AUTOSAR XML (schema 00050)
package /FCADT/ComponentTypes
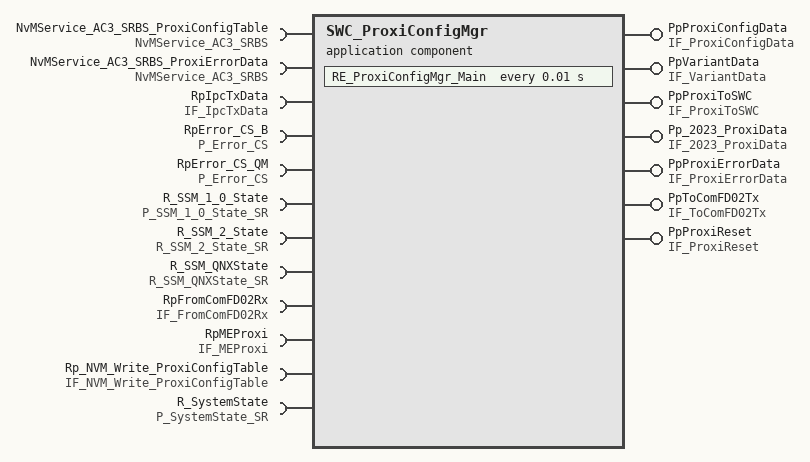
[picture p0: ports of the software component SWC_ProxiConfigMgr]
  application sw component type SWC_ProxiConfigMgr
    provide port PpProxiConfigData: nonqueued-sender-com-spec{data-element=ProxiData, init-value=fields=[bValid:0, ConfigCode:11 x 0, TesterCode:10 x 0, ProductionDate:[0, 0, 0, 0], CanNode14trscm_uint8:0, Variant_ID:0, CanNode27Asm_uint8:0, CanNode63ttm_uint8:0, CanNode67dtcm_uint8:0, CanNode95itcm_uint8:0, StopandStart:0, DriverSide:0, Tyresize_uint16:0, Wheelbase:0, Rearviewcamera:0, Parkwithstop:0, SteeringRatio_uint8:0, Gearboxtype:0, Drivetypevariant:0, Pamtuningset:0, Semiautopark:0, VehicleLineConfiguration_uint8:0, CountryCode_uint8:0, Srt:0, PAMConfig_uint8:0, ModelYear_uint8:0, Hybridtype:0, Pulloutcontrol:0, Surroundviewcamera:0, Forwardfacingcamera:0, Autonomylevel:0, Fullautomaticparking:0, Radiodisplay:0, Mirrortype:0, Auxiliarycamera:0, Trailerreverseguide:0, Trailersurround:0, Trailerreversesteering:0, Trailerhitchassist:0, CVPAM_Presence_uint8:0, SideDistanceWarning:0, PROXIWriteCounter:0]}, provided-interface=IF_ProxiConfigData
    provide port PpVariantData: nonqueued-sender-com-spec{data-element=Variant, init-value=constant-reference=init_Variant}, provided-interface=IF_VariantData
    5 x require port:
      NvMService_AC3_SRBS_ProxiConfigTable: required-com-specs=[WriteBlock, SetRamBlockStatus, ReadBlock, InvalidateNvBlock, GetErrorStatus, EraseBlock], required-interface=NvMService_AC3_SRBS
      NvMService_AC3_SRBS_ProxiErrorData: required-com-specs=[WriteBlock, SetRamBlockStatus, ReadBlock, InvalidateNvBlock, GetErrorStatus, EraseBlock], required-interface=NvMService_AC3_SRBS
      RpIpcTxData: client-com-spec=IPC_Write_v, required-interface=IF_IpcTxData
      RpError_CS_B: client-com-spec=ReportErrorStatus1_0_B, required-interface=P_Error_CS
      RpError_CS_QM: client-com-spec=ReportErrorStatus1_0_QM, required-interface=P_Error_CS
    provide port PpProxiToSWC: provided-interface=IF_ProxiToSWC
      provided-com-specs:
        data-element=TyreSz_u16, init-value=0
        data-element=SurroundViewCam_u8, init-value=0
        data-element=Fullautomaticparking, init-value=0
        data-element=Pamtuningset, init-value=0
        data-element=Parkwithstop_u8, init-value=0
        data-element=Trailerhitchassist_u8, init-value=0
        data-element=PAMConfig_u8, init-value=0
        data-element=PRX_CanNod27_b, init-value=0
    require port R_SSM_1_0_State: nonqueued-receiver-com-spec{data-element=State_1_0, init-value=fields=[CoreStatus:0, LocalAppStatus:20 x 0]}, required-interface=P_SSM_1_0_State_SR
    require port R_SSM_2_State: required-interface=R_SSM_2_State_SR
      required-com-specs:
        data-element=State_2_0, init-value=fields=[CoreStatus:0, LocalAppStatus:20 x 0]
        data-element=State_2_1, filter=data-filter-type=ALWAYS, init-value=fields=[CoreStatus:0, LocalAppStatus:20 x 0]
    require port R_SSM_QNXState: nonqueued-receiver-com-spec{data-element=State_QNX, init-value=fields=[CoreStatus:0, LocalAppStatus:20 x 0]}, required-interface=R_SSM_QNXState_SR
    provide port Pp_2023_ProxiData: server-com-spec{operation=WriteData, queue-length=1}, provided-interface=IF_2023_ProxiData
    provide port PpProxiErrorData: nonqueued-sender-com-spec{data-element=Error, init-value=fields=[ErrorFound:[0, 0, 0], ByteWithError:[0, 0, 0], BitInformationMask:[0, 0, 0]]}, provided-interface=IF_ProxiErrorData
    provide port PpToComFD02Tx: provided-interface=IF_ToComFD02Tx
      provided-com-specs:
        data-element=CurrentCanNMState_FD02_PAM, init-value=0
        data-element=CurrentFailSts_FD02_PAM, init-value=0
        data-element=DES_FD02_PAM, init-value=0
        data-element=Digit_{01..11}_PAM, init-value=0
        data-element=EOL_FD02_PAM, init-value=0
        data-element=GenericFailSts_FD02_PAM, init-value=0
        {data-element=N_PDU, init-value=[rule-based-values={rule=FILL_UNTIL_END, rule-arguments=0}]}
        data-element=PreviousCanNMState_FD02_PAM, init-value=0
        {data-element=StayActiveSource_FD02_PAM, init-value=[rule-based-values={rule=FILL_UNTIL_END, rule-arguments=0}]}
        data-element=THA_EPB_Req, init-value=0
        data-element=THA_Speed_Limit, init-value=0
        data-element=THA_SpeedLimit_Req, init-value=0
        data-element=THA_STAT, init-value=0
        data-element=THA_SteeringDamping, init-value=78.125
        data-element=THA_SteeringTorqueInfo, init-value=0
        data-element=THA_SteeringTorqueReq, init-value=0
        data-element=Trailer_Angle, init-value=0
        data-element=Trailer_Angle_Sign, init-value=0
        data-element=Trailer_Calibration, init-value=0
        data-element=TrlrHitchLight_Cntrl, init-value=0
        data-element=TRSC_PopupDisp_Info, init-value=0
        data-element=TRSC_SpeedLimit_Req, init-value=0
        data-element=TRSC_STAT, init-value=1
        data-element=TRSC_SteeringDamping, init-value=100
        data-element=TRSC_SteeringTorqueInfo, init-value=0
        data-element=TRSC_SteeringTorqueReq, init-value=0
        data-element=TRSC_VehicleStop_Req, init-value=3
        data-element=TRSCMoreCamRQSts, init-value=0
        data-element=WakeupSource_FD02_PAM, init-value=0
        data-element=TRSC_PopupDisp_Info2, init-value=0
    require port RpFromComFD02Rx: required-interface=IF_FromComFD02Rx
      required-com-specs:
        data-element=Altitude_RMSE_C2, init-value=255
        data-element=Battery_Volt_1, init-value=0
        data-element=BSM_THA_Brk_Resp, init-value=0
        data-element=CurrentCanNMState_FD01_BCM, init-value=0
        data-element=CurrentCanNMState_FD01_SGW, init-value=0
        data-element=CurrentCanNMState_FD02_BCM, init-value=0
        data-element=CurrentCanNMState_FD02_BSM2, init-value=0
        data-element=CurrentCanNMState_FD02_CADM2, init-value=0
        data-element=CurrentCanNMState_FD02_EPS, init-value=0
        data-element=CurrentCanNMState_FD02_ORC, init-value=0
        data-element=CurrentCanNMState_FD02_SGW, init-value=0
        data-element=CurrentCanNMState_FD02_TRLR_REV, init-value=0
        data-element=CurrentCanNMState_FD03_BCM, init-value=0
        data-element=CurrentCanNMState_FD03_SGW, init-value=0
        data-element=CurrentCanNMState_FD04_BCM, init-value=0
        data-element=CurrentCanNMState_FD08_SGW, init-value=0
        data-element=CurrentCanNMState_FD11_SGW, init-value=0
        data-element=CurrentFailSts_FD01_BCM, init-value=0
        data-element=CurrentFailSts_FD01_SGW, init-value=0
        data-element=CurrentFailSts_FD02_BCM, init-value=0
        data-element=CurrentFailSts_FD02_BSM2, init-value=0
        data-element=CurrentFailSts_FD02_CADM2, init-value=0
        data-element=CurrentFailSts_FD02_EPS, init-value=0
        data-element=CurrentFailSts_FD02_ORC, init-value=0
        data-element=CurrentFailSts_FD02_SGW, init-value=0
        data-element=CurrentFailSts_FD02_TRLR_REV, init-value=0
        data-element=CurrentFailSts_FD03_BCM, init-value=0
        data-element=CurrentFailSts_FD03_SGW, init-value=0
        data-element=CurrentFailSts_FD04_BCM, init-value=0
        data-element=CurrentFailSts_FD08_SGW, init-value=0
        data-element=CurrentFailSts_FD11_SGW, init-value=0
        data-element=DeltaTimestamp_IMUdata, init-value=255
        data-element=DES_FD01_BCM, init-value=0
        data-element=DES_FD01_SGW, init-value=0
        data-element=DES_FD02_BCM, init-value=0
        data-element=DES_FD02_BSM2, init-value=0
        data-element=DES_FD02_CADM2, init-value=0
        data-element=DES_FD02_EPS, init-value=0
        data-element=DES_FD02_ORC, init-value=0
        data-element=DES_FD02_SGW, init-value=0
        data-element=DES_FD02_TRLR_REV, init-value=0
        data-element=DES_FD03_BCM, init-value=0
        data-element=DES_FD03_SGW, init-value=0
        data-element=DES_FD04_BCM, init-value=0
        data-element=DES_FD08_SGW, init-value=0
        data-element=DES_FD11_SGW, init-value=0
        data-element=Digit_{01..11}, init-value=0
        data-element=EOL_FD01_BCM, init-value=0
        data-element=EOL_FD01_SGW, init-value=0
        data-element=EOL_FD02_BCM, init-value=0
        data-element=EOL_FD02_BSM2, init-value=0
        data-element=EOL_FD02_CADM2, init-value=0
        data-element=EOL_FD02_EPS, init-value=0
        data-element=EOL_FD02_ORC, init-value=0
        data-element=EOL_FD02_SGW, init-value=0
        data-element=EOL_FD02_TRLR_REV, init-value=0
        data-element=EOL_FD03_BCM, init-value=0
        data-element=EOL_FD03_SGW, init-value=0
        data-element=EOL_FD04_BCM, init-value=0
        data-element=EOL_FD08_SGW, init-value=0
        data-element=EOL_FD11_SGW, init-value=0
        data-element=EPBSts, init-value=0
        data-element=GenericFailSts_FD01_BCM, init-value=0
        data-element=GenericFailSts_FD01_SGW, init-value=0
        data-element=GenericFailSts_FD02_BCM, init-value=0
        data-element=GenericFailSts_FD02_BSM2, init-value=0
        data-element=GenericFailSts_FD02_CADM2, init-value=0
        data-element=GenericFailSts_FD02_EPS, init-value=0
        data-element=GenericFailSts_FD02_ORC, init-value=0
        data-element=GenericFailSts_FD02_SGW, init-value=0
        data-element=GenericFailSts_FD02_TRLR_REV, init-value=0
        data-element=GenericFailSts_FD03_BCM, init-value=0
        data-element=GenericFailSts_FD03_SGW, init-value=0
        data-element=GenericFailSts_FD04_BCM, init-value=0
        data-element=GenericFailSts_FD08_SGW, init-value=0
        data-element=GenericFailSts_FD11_SGW, init-value=0
        data-element=Heading_Angle_C2, init-value=65535
        data-element=IgnitionOnCounter, init-value=0
        data-element=LatAcceleration_C2, init-value=4095
        data-element=LatAccelerationOffset_BSM, init-value=255
        data-element=Latitude_RMSE_C2, init-value=255
        data-element=LHF_FastPulseCounter, init-value=0
        data-element=LHF_Spin, init-value=0
        data-element=LHFWheelSpeed, init-value=0
        data-element=LHR_FastPulseCounter, init-value=0
        data-element=LHR_Spin, init-value=0
        data-element=LHRWheelSpeed, init-value=0
        data-element=LongAcceleration_C2, init-value=4095
        data-element=LongAccelerationOffset_BSM, init-value=255
        data-element=Longitude_RMSE_C2, init-value=255
        data-element=OperationalModeSts, init-value=0
        data-element=Pitch_RMSE_C2, init-value=255
        data-element=PitchRate_C2, init-value=4095
        data-element=PreviousCanNMState_FD01_BCM, init-value=0
        data-element=PreviousCanNMState_FD01_SGW, init-value=0
        data-element=PreviousCanNMState_FD02_BCM, init-value=0
        data-element=PreviousCanNMState_FD02_BSM2, init-value=0
        data-element=PreviousCanNMState_FD02_CADM2, init-value=0
        data-element=PreviousCanNMState_FD02_EPS, init-value=0
        data-element=PreviousCanNMState_FD02_ORC, init-value=0
        data-element=PreviousCanNMState_FD02_SGW, init-value=0
        data-element=PreviousCanNMState_FD02_TRLR_REV, init-value=0
        data-element=PreviousCanNMState_FD03_BCM, init-value=0
        data-element=PreviousCanNMState_FD03_SGW, init-value=0
        data-element=PreviousCanNMState_FD04_BCM, init-value=0
        data-element=PreviousCanNMState_FD08_SGW, init-value=0
        data-element=PreviousCanNMState_FD11_SGW, init-value=0
        data-element=REF_VEH_SPEED, init-value=1023
        data-element=RemStActvSts, init-value=0
        data-element=RHF_FastPulseCounter, init-value=0
        data-element=RHF_Spin, init-value=0
        data-element=RHFWheelSpeed, init-value=0
        data-element=RHR_FastPulseCounter, init-value=0
        data-element=RHR_Spin, init-value=0
        data-element=RHRWheelSpeed, init-value=0
        data-element=Roll_RMSE_C2, init-value=255
        data-element=RollRate_C2, init-value=4095
        data-element=SBR1RowDriverSeatSts, init-value=3
        data-element=StayActiveSource_FD01_BCM, init-value=0
        data-element=StayActiveSource_FD01_SGW, init-value=0
        data-element=StayActiveSource_FD02_BCM, init-value=0
        data-element=StayActiveSource_FD02_BSM2, init-value=0
        data-element=StayActiveSource_FD02_CADM2, init-value=0
        data-element=StayActiveSource_FD02_EPS, init-value=0
        data-element=StayActiveSource_FD02_ORC, init-value=0
        data-element=StayActiveSource_FD02_SGW, init-value=0
        data-element=StayActiveSource_FD02_TRLR_REV, init-value=0
        data-element=StayActiveSource_FD03_BCM, init-value=0
        data-element=StayActiveSource_FD03_SGW, init-value=0
        data-element=StayActiveSource_FD04_BCM, init-value=0
        data-element=StayActiveSource_FD08_SGW, init-value=0
        data-element=StayActiveSource_FD11_SGW, init-value=0
        data-element=TotalOdometer, init-value=0
        data-element=TRSC_CenterBtn_Sts, init-value=0
        data-element=TRSC_EnableBtn_Sts, init-value=0
        data-element=TRSC_RawKnob, init-value=0
        data-element=TurnIndicatorSts, init-value=0
        data-element=VehicleStandStillSts, init-value=1
        data-element=VerticalAcceleration_C2, init-value=4095
        data-element=WakeupSource_FD01_ADCM, init-value=0
        data-element=WakeupSource_FD01_BCM, init-value=0
        data-element=WakeupSource_FD01_SGW, init-value=0
        data-element=WakeupSource_FD02_BCM, init-value=0
        data-element=WakeupSource_FD02_BSM2, init-value=0
        data-element=WakeupSource_FD02_CADM2, init-value=0
        data-element=WakeupSource_FD02_EPS, init-value=0
        data-element=WakeupSource_FD02_ORC, init-value=0
        data-element=WakeupSource_FD02_SGW, init-value=0
        data-element=WakeupSource_FD02_TRLR_REV, init-value=0
        data-element=WakeupSource_FD03_BCM, init-value=0
        data-element=WakeupSource_FD03_SGW, init-value=0
        data-element=WakeupSource_FD04_BCM, init-value=0
        data-element=WakeupSource_FD08_SGW, init-value=0
        data-element=WakeupSource_FD11_SGW, init-value=0
        data-element=YawRate_C2, init-value=4095
        data-element=YawRate_RMSE_C2, init-value=255
    require port RpMEProxi: nonqueued-receiver-com-spec{data-element=ME_Proxi_MPU1_0_to_MCU1_0_t, filter=data-filter-type=ALWAYS, init-value=fields=[a72_cpu_load:0, state:0, PRX_RadioDispTyp_u8:0, PRX_variantID_u8:0]}, required-interface=IF_MEProxi
    provide port PpProxiReset: nonqueued-sender-com-spec{data-element=ProxiDataflag_b, init-value=0}, provided-interface=IF_ProxiReset
    require port Rp_NVM_Write_ProxiConfigTable: client-com-spec=ProxiconfigTable_Nvm_write_confirmation, required-interface=IF_NVM_Write_ProxiConfigTable
    require port R_SystemState: nonqueued-receiver-com-spec=data-element=SystemState, required-interface=P_SystemState_SR
    behavior SWC_ProxiConfigMgr_InternalBehavior: data-type-mapping=DataTypeMappings_DEV, handle-termination-and-restart=NO-SUPPORT
      ar-typed-per-instance-memorys:
        data ProxiConfigTable_MirrorBlock: sw-calibration-access=READ-ONLY, type=ME_Hydra2defs_S_CodingTableExt_t
        data ProxiErrorData_MirrorBlock: sw-calibration-access=READ-ONLY, type=ME_Hydra2defs_S_PROXI_error_Data_t
      init event InitEvent: start-on-event=RE_ProxiConfigMgr_Init
      timing event TMT_RE_ProxiConfigMgr_Main: start-on-event=RE_ProxiConfigMgr_Main, period=0.01
      operation invoked event OIT_RE_DID2023_ProxiData_Pp_2023_ProxiData_WriteData: start-on-event=RE_DID2023_ProxiData, operation=Pp_2023_ProxiData.WriteData
      data received event DRT_RE_ProxiMgr_ConfigDataRSP_RpFromComFD02Rx_Digit_01: start-on-event=RE_ProxiMgr_ConfigDataRSP, data=RpFromComFD02Rx.Digit_01
      per-instance-parameters:
        parameter data prototype ProxiConfigTable_DefaultValue:
          sw-calibration-access=READ-WRITE
          type=ME_Hydra2defs_S_CodingTableExt_t
          init-value=fields=[bValid:0, ConfigCode:11 x 0, TesterCode:10 x 0, ProductionDate:[0, 0, 0, 0], CanNode14trscm_uint8:0, Variant_ID:8, CanNode27Asm_uint8:0, CanNode63ttm_uint8:0, CanNode67dtcm_uint8:1, CanNode95itcm_uint8:1, StopandStart:1, DriverSide:0, Tyresize_uint16:2514, Wheelbase:1, Rearviewcamera:0, Parkwithstop:1, SteeringRatio_uint8:1, Gearboxtype:4, Drivetypevariant:1, Pamtuningset:1, Semiautopark:0, VehicleLineConfiguration_uint8:124, CountryCode_uint8:2, Srt:0, PAMConfig_uint8:1, ModelYear_uint8:27, Hybridtype:0, Pulloutcontrol:0, Surroundviewcamera:1, Forwardfacingcamera:0, Autonomylevel:1, Fullautomaticparking:1, Radiodisplay:7, Mirrortype:3, Auxiliarycamera:0, Trailerreverseguide:0, Trailersurround:0, Trailerreversesteering:0, Trailerhitchassist:0, CVPAM_Presence_uint8:1, SideDistanceWarning:0, PROXIWriteCounter:0]
        parameter data prototype ProxiErrorData_DefaultValue: sw-calibration-access=READ-WRITE, type=ME_Hydra2defs_S_PROXI_error_Data_t, init-value=fields=[ErrorFound:[0, 0, 0], ByteWithError:[0, 0, 0], BitInformationMask:[0, 0, 0]]
      port-api-options:
        enable-take-address=false, error-handling=NO-TRANSFORMER-ERROR-HANDLING, indirect-api=false, port=PpProxiConfigData
        enable-take-address=false, error-handling=NO-TRANSFORMER-ERROR-HANDLING, indirect-api=false, port=PpVariantData
      4 x runnable:
        RE_ProxiConfigMgr_Init
        RE_ProxiConfigMgr_Main
          data-receive-point-by-arguments:
            7 x access:
              REC_R_SSM_1_0_State_State_1_0: accessed-variable=R_SSM_1_0_State.State_1_0
              REC_R_SSM_2_State_State_2_0: accessed-variable=R_SSM_2_State.State_2_0
              REC_R_SSM_2_State_State_2_1: accessed-variable=R_SSM_2_State.State_2_1
              REC_R_SSM_QNXState_State_QNX: accessed-variable=R_SSM_QNXState.State_QNX
              REC_RpFromComFD02Rx_TotalOdometer: accessed-variable=RpFromComFD02Rx.TotalOdometer
              REC_RpMEProxi_ME_Proxi_MPU1_0_to_MCU1_0_t: accessed-variable=RpMEProxi.ME_Proxi_MPU1_0_to_MCU1_0_t
              REC_R_SystemState_SystemState: accessed-variable=R_SystemState.SystemState
          data-send-points:
            13 x access:
              SEND_PpProxiConfigData_ProxiData: accessed-variable=PpProxiConfigData.ProxiData
              SEND_PpVariantData_Variant: accessed-variable=PpVariantData.Variant
              SEND_PpProxiToSWC_SurroundViewCam_u8: accessed-variable=PpProxiToSWC.SurroundViewCam_u8
              SEND_PpProxiToSWC_TyreSz_u16: accessed-variable=PpProxiToSWC.TyreSz_u16
              SEND_PpProxiErrorData_Error: accessed-variable=PpProxiErrorData.Error
              SEND_PpToComFD02Tx_EOL_FD02_PAM: accessed-variable=PpToComFD02Tx.EOL_FD02_PAM
              SEND_PpProxiReset_ProxiDataflag_b: accessed-variable=PpProxiReset.ProxiDataflag_b
              SEND_PpProxiToSWC_Fullautomaticparking: accessed-variable=PpProxiToSWC.Fullautomaticparking
              SEND_PpProxiToSWC_Pamtuningset: accessed-variable=PpProxiToSWC.Pamtuningset
              SEND_PpProxiToSWC_PAMConfig_u8: accessed-variable=PpProxiToSWC.PAMConfig_u8
              SEND_PpProxiToSWC_Parkwithstop_u8: accessed-variable=PpProxiToSWC.Parkwithstop_u8
              SEND_PpProxiToSWC_Trailerhitchassist_u8: accessed-variable=PpProxiToSWC.Trailerhitchassist_u8
              SEND_PpProxiToSWC_PRX_CanNod27_b: accessed-variable=PpProxiToSWC.PRX_CanNod27_b
          7 x sync call:
            SC_NvMService_AC3_SRBS_ProxiErrorData_SetRamBlockStatus: operation=NvMService_AC3_SRBS_ProxiErrorData.SetRamBlockStatus
            SC_NvMService_AC3_SRBS_ProxiConfigTable_WriteBlock: operation=NvMService_AC3_SRBS_ProxiConfigTable.WriteBlock
            SC_RpIpcTxData_IPC_Write_v: operation=RpIpcTxData.IPC_Write_v
            SC_RpError_CS_B_ReportErrorStatus1_0_B: operation=RpError_CS_B.ReportErrorStatus1_0_B
            SC_RpError_CS_QM_ReportErrorStatus1_0_QM: operation=RpError_CS_QM.ReportErrorStatus1_0_QM
            SC_Rp_NVM_Write_ProxiConfigTable_ProxiconfigTable_Nvm_write_confirmation: operation=Rp_NVM_Write_ProxiConfigTable.ProxiconfigTable_Nvm_write_confirmation
            SC_NvMService_AC3_SRBS_ProxiConfigTable_GetErrorStatus: operation=NvMService_AC3_SRBS_ProxiConfigTable.GetErrorStatus
        RE_ProxiMgr_ConfigDataRSP
          data-send-points:
            11 x access:
              SEND_PpToComFD02Tx_Digit_{01..11}_PAM: accessed-variable=PpToComFD02Tx.Digit_{01..11}_PAM
        RE_DID2023_ProxiData
      swc service dependency ProxiConfigTable: category=SERVICE, assigned-datas=role-based-data-assignment={role=defaultValue, used-parameter-element=ProxiConfigTable_DefaultValue}, assigned-ports=role-based-port-assignment={port-prototype=NvMService_AC3_SRBS_ProxiConfigTable, role=NvMService_AC3_SRBS}
        service-needs:
          nv block needs ProxiConfigTable: calc-ram-block-crc=true, check-static-block-id=false, n-data-sets=0, ram-block-status-control=API, readonly=false, reliability=ERROR-CORRECTION, resistant-to-changed-sw=true, restore-at-start=true, store-at-shutdown=false, store-cyclic=false, store-emergency=false, store-immediate=true, use-auto-validation-at-shut-down=false, use-crc-comp-mechanism=true, write-only-once=false, write-verification=false
      swc service dependency ProxiErrorData: category=SERVICE, assigned-datas=role-based-data-assignment={role=defaultValue, used-parameter-element=ProxiErrorData_DefaultValue}, assigned-ports=role-based-port-assignment={port-prototype=NvMService_AC3_SRBS_ProxiErrorData, role=NvMService_AC3_SRBS}
        service-needs:
          nv block needs ProxiErrorData: n-data-sets=1, ram-block-status-control=API, reliability=NO-PROTECTION, restore-at-start=true, store-at-shutdown=true
  swc implementation SWC_ProxiConfigMgr_Implementation: programming-language=C, vendor-id=0, behavior=SWC_ProxiConfigMgr_InternalBehavior
    code-descriptors:
      code Default: artifact-descriptors=autosar-engineering-object=category=SWSRC
